# ATSAMC21N17A register map
Registers are 32-bit, access not given, no defined reset value unless marked. A register's access mark holds for its fields unless they carry their own. Addresses are absolute; registers are grouped by the start of their names; [hi:lo] are bit positions; {n}, {i} and the like mark numbered series.

## ADC1
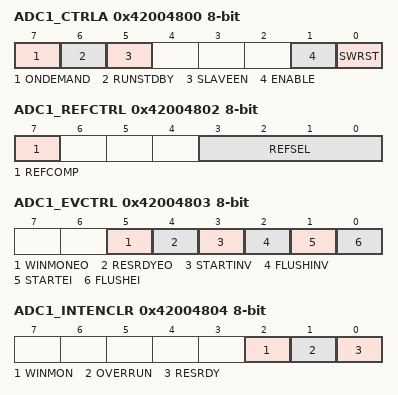
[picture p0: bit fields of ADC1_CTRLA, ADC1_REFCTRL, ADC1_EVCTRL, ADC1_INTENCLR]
0x42004800 ADC1_CTRLA 8-bit — Control A
  [7] ONDEMAND, [6] RUNSTDBY, [5] SLAVEEN, [1] ENABLE, [0] SWRST
0x42004801 ADC1_CTRLB 8-bit — Control B
  [2:0] PRESCALER
0x42004802 ADC1_REFCTRL 8-bit — Reference Control
  [7] REFCOMP, [3:0] REFSEL
0x42004803 ADC1_EVCTRL 8-bit — Event Control
  [5] WINMONEO, [4] RESRDYEO, [3] STARTINV, [2] FLUSHINV, [1] STARTEI, [0] FLUSHEI
0x42004804 ADC1_INTENCLR 8-bit — Interrupt Enable Clear
  [2] WINMON, [1] OVERRUN, [0] RESRDY
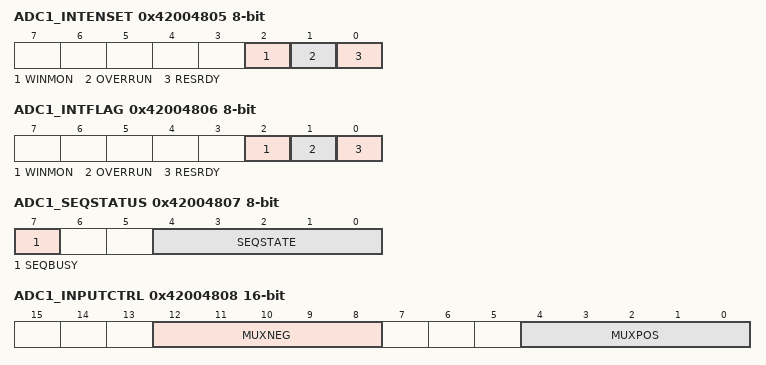
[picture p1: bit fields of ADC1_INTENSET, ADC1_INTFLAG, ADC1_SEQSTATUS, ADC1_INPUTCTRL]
0x42004805 ADC1_INTENSET 8-bit — Interrupt Enable Set
  [2] WINMON, [1] OVERRUN, [0] RESRDY
0x42004806 ADC1_INTFLAG 8-bit — Interrupt Flag Status and Clear
  [2] WINMON, [1] OVERRUN, [0] RESRDY
0x42004807 ADC1_SEQSTATUS 8-bit — Sequence Status
  [7] SEQBUSY, [4:0] SEQSTATE
0x42004808 ADC1_INPUTCTRL 16-bit — Input Control
  [12:8] MUXNEG, [4:0] MUXPOS
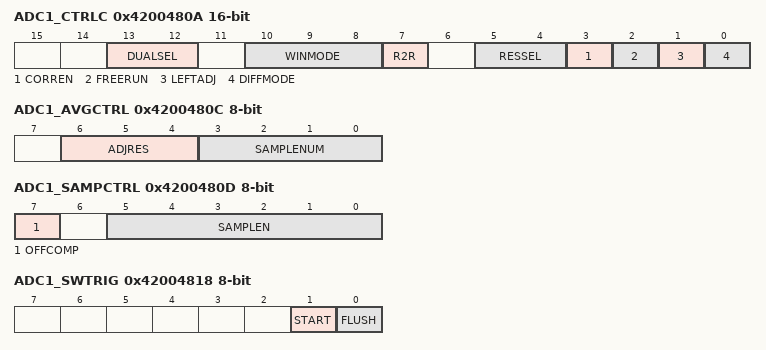
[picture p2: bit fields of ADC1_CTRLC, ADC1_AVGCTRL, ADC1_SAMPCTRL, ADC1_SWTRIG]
0x4200480A ADC1_CTRLC 16-bit — Control C
  [13:12] DUALSEL, [10:8] WINMODE, [7] R2R, [5:4] RESSEL, [3] CORREN, [2] FREERUN, [1] LEFTADJ, [0] DIFFMODE
0x4200480C ADC1_AVGCTRL 8-bit — Average Control
  [6:4] ADJRES, [3:0] SAMPLENUM
0x4200480D ADC1_SAMPCTRL 8-bit — Sample Time Control
  [7] OFFCOMP, [5:0] SAMPLEN
0x4200480E ADC1_WINLT 16-bit — Window Monitor Lower Threshold
0x42004810 ADC1_WINUT 16-bit — Window Monitor Upper Threshold
0x42004812 ADC1_GAINCORR 16-bit — Gain Correction
  [11:0] GAINCORR
0x42004814 ADC1_OFFSETCORR 16-bit — Offset Correction
  [11:0] OFFSETCORR
0x42004818 ADC1_SWTRIG 8-bit — Software Trigger
  [1] START, [0] FLUSH
0x4200481C ADC1_DBGCTRL 8-bit — Debug Control
  [0] DBGRUN
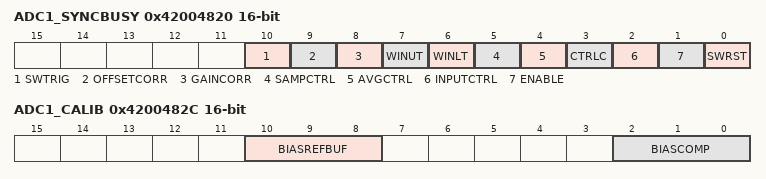
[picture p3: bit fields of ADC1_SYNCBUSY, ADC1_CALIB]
0x42004820 ADC1_SYNCBUSY 16-bit — Synchronization Busy
  [10] SWTRIG, [9] OFFSETCORR, [8] GAINCORR, [7] WINUT, [6] WINLT, [5] SAMPCTRL, [4] AVGCTRL, [3] CTRLC, [2] INPUTCTRL, [1] ENABLE, [0] SWRST
0x42004824 ADC1_RESULT 16-bit — Result
0x42004828 ADC1_SEQCTRL — Sequence Control
  [31:0] SEQEN
0x4200482C ADC1_CALIB 16-bit — Calibration
  [10:8] BIASREFBUF, [2:0] BIASCOMP

## CCL
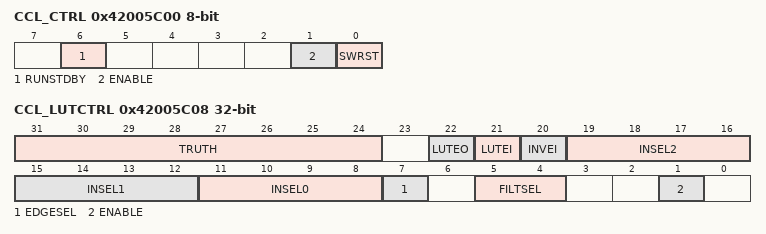
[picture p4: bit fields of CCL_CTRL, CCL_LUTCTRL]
0x42005C00 CCL_CTRL 8-bit — Control
  [6] RUNSTDBY, [1] ENABLE, [0] SWRST
0x42005C04 CCL_SEQCTRL 8-bit — SEQ Control x
  [3:0] SEQSEL
0x42005C08 CCL_LUTCTRL — LUT Control x
  [31:24] TRUTH, [22] LUTEO, [21] LUTEI, [20] INVEI, [19:16] INSEL2, [15:12] INSEL1, [11:8] INSEL0, [7] EDGESEL, [5:4] FILTSEL, [1] ENABLE

## DAC
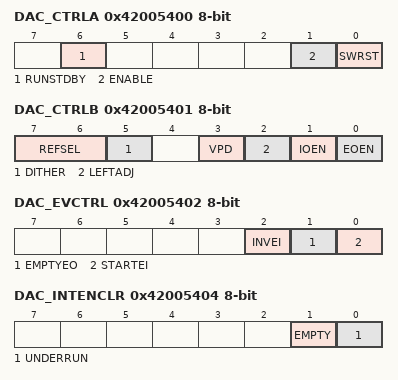
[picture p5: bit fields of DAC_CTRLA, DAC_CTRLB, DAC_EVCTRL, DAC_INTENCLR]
0x42005400 DAC_CTRLA 8-bit — Control A
  [6] RUNSTDBY, [1] ENABLE, [0] SWRST
0x42005401 DAC_CTRLB 8-bit — Control B
  [7:6] REFSEL, [5] DITHER, [3] VPD, [2] LEFTADJ, [1] IOEN, [0] EOEN
0x42005402 DAC_EVCTRL 8-bit — Event Control
  [2] INVEI, [1] EMPTYEO, [0] STARTEI
0x42005404 DAC_INTENCLR 8-bit — Interrupt Enable Clear
  [1] EMPTY, [0] UNDERRUN
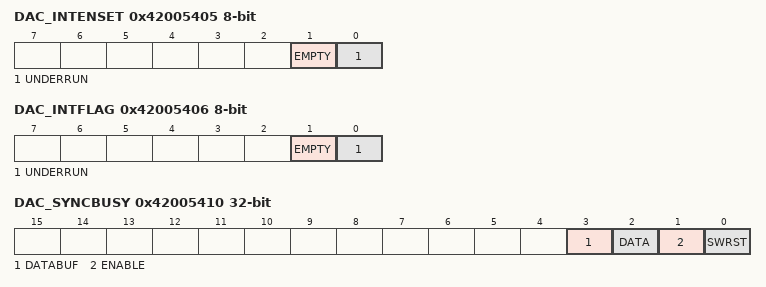
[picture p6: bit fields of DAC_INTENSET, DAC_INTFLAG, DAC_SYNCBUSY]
0x42005405 DAC_INTENSET 8-bit — Interrupt Enable Set
  [1] EMPTY, [0] UNDERRUN
0x42005406 DAC_INTFLAG 8-bit — Interrupt Flag Status and Clear
  [1] EMPTY, [0] UNDERRUN
0x42005407 DAC_STATUS 8-bit — Status
  [0] READY
0x42005408 DAC_DATA 16-bit — Data
0x4200540C DAC_DATABUF 16-bit — Data Buffer
0x42005410 DAC_SYNCBUSY — Synchronization Busy
  [3] DATABUF, [2] DATA, [1] ENABLE, [0] SWRST
0x42005414 DAC_DBGCTRL 8-bit — Debug Control
  [0] DBGRUN

## DIVAS
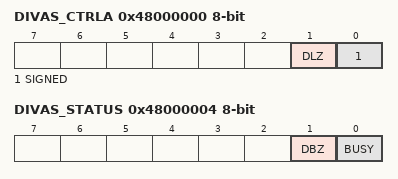
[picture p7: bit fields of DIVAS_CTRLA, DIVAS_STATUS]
0x48000000 DIVAS_CTRLA 8-bit — Control
  [1] DLZ, [0] SIGNED
0x48000004 DIVAS_STATUS 8-bit — Status
  [1] DBZ, [0] BUSY
0x48000008 DIVAS_DIVIDEND — Dividend
0x4800000C DIVAS_DIVISOR — Divisor
0x48000010 DIVAS_RESULT — Result
0x48000014 DIVAS_REM — Remainder
0x48000018 DIVAS_SQRNUM — Square Root Input

## DMAC
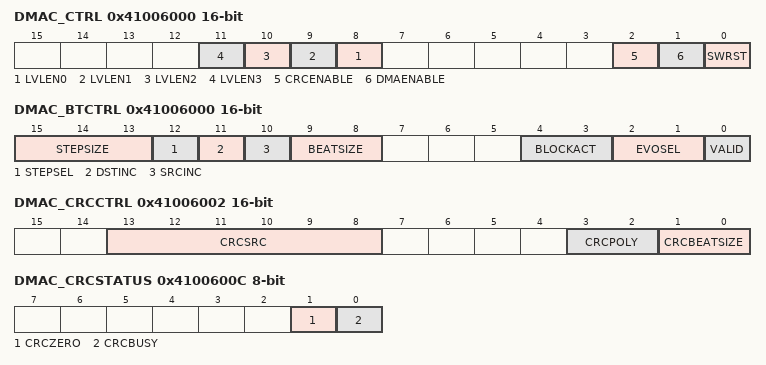
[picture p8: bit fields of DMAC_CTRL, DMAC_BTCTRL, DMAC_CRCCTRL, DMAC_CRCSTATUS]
0x41006000 DMAC_CTRL 16-bit — Control
  [n+8] LVLEN{n} (n=0..3), [2] CRCENABLE, [1] DMAENABLE, [0] SWRST
0x41006000 DMAC_BTCTRL 16-bit — Block Transfer Control
  [15:13] STEPSIZE, [12] STEPSEL, [11] DSTINC, [10] SRCINC, [9:8] BEATSIZE, [4:3] BLOCKACT, [2:1] EVOSEL, [0] VALID
0x41006002 DMAC_CRCCTRL 16-bit — CRC Control
  [13:8] CRCSRC, [3:2] CRCPOLY, [1:0] CRCBEATSIZE
0x41006002 DMAC_BTCNT 16-bit — Block Transfer Count
0x41006004 DMAC_CRCDATAIN — CRC Data Input
0x41006004 DMAC_SRCADDR — Block Transfer Source Address
0x41006008 DMAC_CRCCHKSUM — CRC Checksum
0x41006008 DMAC_DSTADDR — Block Transfer Destination Address
0x4100600C DMAC_CRCSTATUS 8-bit — CRC Status
  [1] CRCZERO, [0] CRCBUSY
0x4100600C DMAC_DESCADDR — Next Descriptor Address
0x4100600D DMAC_DBGCTRL 8-bit — Debug Control
  [0] DBGRUN
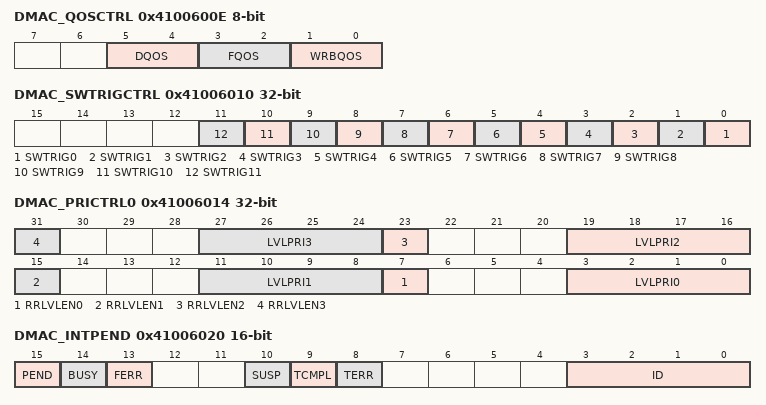
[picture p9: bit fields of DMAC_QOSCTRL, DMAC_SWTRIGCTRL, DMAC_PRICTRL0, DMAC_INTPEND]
0x4100600E DMAC_QOSCTRL 8-bit — QOS Control
  [5:4] DQOS, [3:2] FQOS, [1:0] WRBQOS
0x41006010 DMAC_SWTRIGCTRL — Software Trigger Control
  [n] SWTRIG{n} (n=0..11)
0x41006014 DMAC_PRICTRL0 — Priority Control 0
  [8n+7] RRLVLEN{n} (n=0..3), [8n+3:8n] LVLPRI{n} (n=0..3)
0x41006020 DMAC_INTPEND 16-bit — Interrupt Pending
  [15] PEND, [14] BUSY, [13] FERR, [10] SUSP, [9] TCMPL, [8] TERR, [3:0] ID
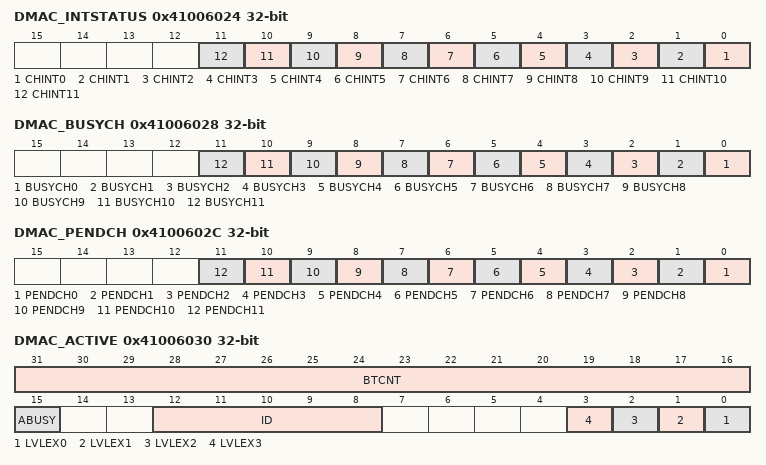
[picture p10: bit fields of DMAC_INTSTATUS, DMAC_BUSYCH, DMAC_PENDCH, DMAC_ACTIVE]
0x41006024 DMAC_INTSTATUS — Interrupt Status
  [n] CHINT{n} (n=0..11)
0x41006028 DMAC_BUSYCH — Busy Channels
  [n] BUSYCH{n} (n=0..11)
0x4100602C DMAC_PENDCH — Pending Channels
  [n] PENDCH{n} (n=0..11)
0x41006030 DMAC_ACTIVE — Active Channel and Levels
  [31:16] BTCNT, [15] ABUSY, [12:8] ID, [n] LVLEX{n} (n=0..3)
0x41006034 DMAC_BASEADDR — Descriptor Memory Section Base Address
0x41006038 DMAC_WRBADDR — Write-Back Memory Section Base Address
0x4100603F DMAC_CHID 8-bit — Channel ID
  [3:0] ID
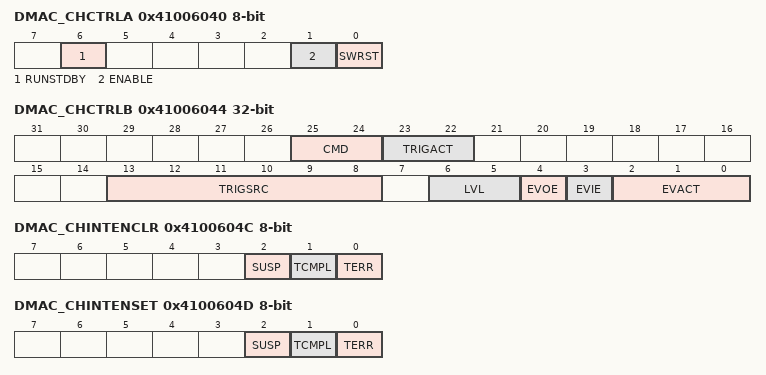
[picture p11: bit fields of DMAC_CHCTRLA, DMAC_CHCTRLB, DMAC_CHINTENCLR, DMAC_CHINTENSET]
0x41006040 DMAC_CHCTRLA 8-bit — Channel Control A
  [6] RUNSTDBY, [1] ENABLE, [0] SWRST
0x41006044 DMAC_CHCTRLB — Channel Control B
  [25:24] CMD, [23:22] TRIGACT, [13:8] TRIGSRC, [6:5] LVL, [4] EVOE, [3] EVIE, [2:0] EVACT
0x4100604C DMAC_CHINTENCLR 8-bit — Channel Interrupt Enable Clear
  [2] SUSP, [1] TCMPL, [0] TERR
0x4100604D DMAC_CHINTENSET 8-bit — Channel Interrupt Enable Set
  [2] SUSP, [1] TCMPL, [0] TERR
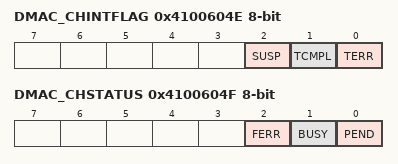
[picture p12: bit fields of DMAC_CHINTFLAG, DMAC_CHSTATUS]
0x4100604E DMAC_CHINTFLAG 8-bit — Channel Interrupt Flag Status and Clear
  [2] SUSP, [1] TCMPL, [0] TERR
0x4100604F DMAC_CHSTATUS 8-bit — Channel Status
  [2] FERR, [1] BUSY, [0] PEND
